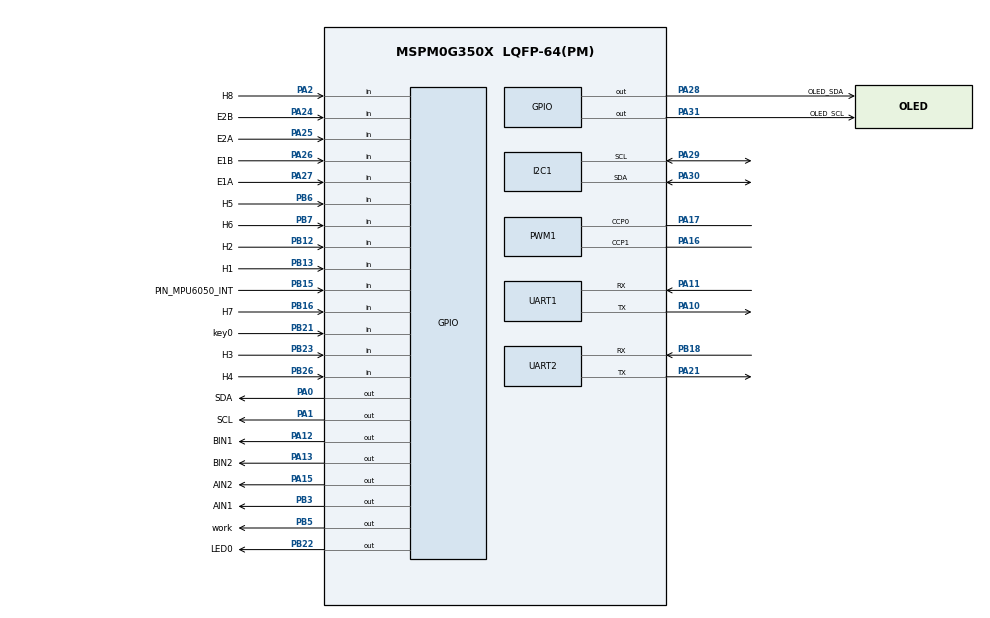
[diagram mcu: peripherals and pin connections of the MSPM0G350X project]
/**
 * @cliArgs --device "MSPM0G350X" --part "Default" --package "LQFP-64(PM)" --product "mspm0_sdk@2.10.00.04"
 * @versions {"tool":"1.27.0+4565"}
 */

/**
 * Import the modules used in this configuration.
 */
const GPIO   = scripting.addModule("/ti/driverlib/GPIO", {}, false);
const GPIO1  = GPIO.addInstance();
const GPIO2  = GPIO.addInstance();
const GPIO3  = GPIO.addInstance();
const GPIO4  = GPIO.addInstance();
const GPIO5  = GPIO.addInstance();
const GPIO6  = GPIO.addInstance();
const GPIO7  = GPIO.addInstance();
const GPIO8  = GPIO.addInstance();
const GPIO9  = GPIO.addInstance();
const I2C    = scripting.addModule("/ti/driverlib/I2C", {}, false);
const I2C1   = I2C.addInstance();
const PWM    = scripting.addModule("/ti/driverlib/PWM", {}, false);
const PWM1   = PWM.addInstance();
const SYSCTL = scripting.addModule("/ti/driverlib/SYSCTL");
const TIMER  = scripting.addModule("/ti/driverlib/TIMER", {}, false);
const TIMER1 = TIMER.addInstance();
const UART   = scripting.addModule("/ti/driverlib/UART", {}, false);
const UART1  = UART.addInstance();
const UART2  = UART.addInstance();

/**
 * Write custom configuration values to the imported modules.
 */
GPIO1.$name                               = "ENCODER";
GPIO1.port                                = "PORTA";
GPIO1.associatedPins.create(4);
GPIO1.associatedPins[0].$name             = "E1A";
GPIO1.associatedPins[0].direction         = "INPUT";
GPIO1.associatedPins[0].interruptEn       = true;
GPIO1.associatedPins[0].polarity          = "RISE";
GPIO1.associatedPins[0].internalResistor  = "PULL_DOWN";
GPIO1.associatedPins[0].interruptPriority = "0";
GPIO1.associatedPins[0].assignedPin       = "27";
GPIO1.associatedPins[0].pin.$assign       = "PA27";
GPIO1.associatedPins[1].$name             = "E1B";
GPIO1.associatedPins[1].direction         = "INPUT";
GPIO1.associatedPins[1].interruptEn       = true;
GPIO1.associatedPins[1].polarity          = "RISE";
GPIO1.associatedPins[1].internalResistor  = "PULL_DOWN";
GPIO1.associatedPins[1].interruptPriority = "0";
GPIO1.associatedPins[1].assignedPin       = "26";
GPIO1.associatedPins[1].pin.$assign       = "PA26";
GPIO1.associatedPins[2].$name             = "E2A";
GPIO1.associatedPins[2].direction         = "INPUT";
GPIO1.associatedPins[2].interruptEn       = true;
GPIO1.associatedPins[2].polarity          = "RISE";
GPIO1.associatedPins[2].internalResistor  = "PULL_DOWN";
GPIO1.associatedPins[2].interruptPriority = "0";
GPIO1.associatedPins[2].assignedPin       = "25";
GPIO1.associatedPins[2].pin.$assign       = "PA25";
GPIO1.associatedPins[3].$name             = "E2B";
GPIO1.associatedPins[3].direction         = "INPUT";
GPIO1.associatedPins[3].interruptEn       = true;
GPIO1.associatedPins[3].polarity          = "RISE";
GPIO1.associatedPins[3].internalResistor  = "PULL_DOWN";
GPIO1.associatedPins[3].interruptPriority = "0";
GPIO1.associatedPins[3].assignedPin       = "24";
GPIO1.associatedPins[3].pin.$assign       = "PA24";

const Board = scripting.addModule("/ti/driverlib/Board", {}, false);

GPIO2.$name                         = "OLED";
GPIO2.port                          = "PORTA";
GPIO2.associatedPins.create(2);
GPIO2.associatedPins[0].$name       = "OLED_SCL";
GPIO2.associatedPins[0].assignedPin = "31";
GPIO2.associatedPins[0].pin.$assign = "PA31";
GPIO2.associatedPins[1].$name       = "OLED_SDA";
GPIO2.associatedPins[1].assignedPin = "28";
GPIO2.associatedPins[1].pin.$assign = "PA28";

GPIO3.$name                          = "MOTOR";
GPIO3.associatedPins.create(4);
GPIO3.associatedPins[0].$name        = "AIN1";
GPIO3.associatedPins[0].assignedPort = "PORTB";
GPIO3.associatedPins[0].assignedPin  = "3";
GPIO3.associatedPins[0].pin.$assign  = "PB3";
GPIO3.associatedPins[1].$name        = "AIN2";
GPIO3.associatedPins[1].assignedPort = "PORTA";
GPIO3.associatedPins[1].assignedPin  = "15";
GPIO3.associatedPins[1].pin.$assign  = "PA15";
GPIO3.associatedPins[2].$name        = "BIN1";
GPIO3.associatedPins[2].assignedPort = "PORTA";
GPIO3.associatedPins[2].assignedPin  = "12";
GPIO3.associatedPins[2].pin.$assign  = "PA12";
GPIO3.associatedPins[3].$name        = "BIN2";
GPIO3.associatedPins[3].assignedPort = "PORTA";
GPIO3.associatedPins[3].assignedPin  = "13";
GPIO3.associatedPins[3].pin.$assign  = "PA13";

GPIO4.$name                          = "IIC_Software";
GPIO4.port                           = "PORTA";
GPIO4.associatedPins.create(2);
GPIO4.associatedPins[0].$name        = "SDA";
GPIO4.associatedPins[0].initialValue = "SET";
GPIO4.associatedPins[0].ioStructure  = "OD";
GPIO4.associatedPins[0].assignedPin  = "0";
GPIO4.associatedPins[0].pin.$assign  = "PA0";
GPIO4.associatedPins[1].$name        = "SCL";
GPIO4.associatedPins[1].initialValue = "SET";
GPIO4.associatedPins[1].ioStructure  = "OD";
GPIO4.associatedPins[1].assignedPin  = "1";
GPIO4.associatedPins[1].pin.$assign  = "PA1";

GPIO5.$name                               = "GPIO_MPU6050";
GPIO5.associatedPins[0].$name             = "PIN_MPU6050_INT";
GPIO5.associatedPins[0].direction         = "INPUT";
GPIO5.associatedPins[0].internalResistor  = "PULL_UP";
GPIO5.associatedPins[0].interruptEn       = true;
GPIO5.associatedPins[0].interruptPriority = "1";
GPIO5.associatedPins[0].polarity          = "FALL";
GPIO5.associatedPins[0].assignedPort      = "PORTB";
GPIO5.associatedPins[0].assignedPin       = "15";
GPIO5.associatedPins[0].pin.$assign       = "PB15";

GPIO6.$name                         = "citie";
GPIO6.port                          = "PORTB";
GPIO6.associatedPins[0].$name       = "work";
GPIO6.associatedPins[0].assignedPin = "5";
GPIO6.associatedPins[0].pin.$assign = "PB5";

GPIO7.$name                              = "KEY";
GPIO7.associatedPins[0].$name            = "key0";
GPIO7.associatedPins[0].direction        = "INPUT";
GPIO7.associatedPins[0].assignedPort     = "PORTB";
GPIO7.associatedPins[0].assignedPin      = "21";
GPIO7.associatedPins[0].internalResistor = "PULL_UP";
GPIO7.associatedPins[0].pin.$assign      = "PB21";

GPIO8.$name                          = "LED";
GPIO8.associatedPins[0].$name        = "LED0";
GPIO8.associatedPins[0].assignedPort = "PORTB";
GPIO8.associatedPins[0].assignedPin  = "22";
GPIO8.associatedPins[0].pin.$assign  = "PB22";

GPIO9.$name                          = "Huidu";
GPIO9.associatedPins.create(8);
GPIO9.associatedPins[0].$name        = "H1";
GPIO9.associatedPins[0].direction    = "INPUT";
GPIO9.associatedPins[0].assignedPin  = "13";
GPIO9.associatedPins[0].pin.$assign  = "PB13";
GPIO9.associatedPins[1].$name        = "H2";
GPIO9.associatedPins[1].direction    = "INPUT";
GPIO9.associatedPins[1].assignedPin  = "12";
GPIO9.associatedPins[1].pin.$assign  = "PB12";
GPIO9.associatedPins[2].$name        = "H3";
GPIO9.associatedPins[2].direction    = "INPUT";
GPIO9.associatedPins[2].assignedPin  = "23";
GPIO9.associatedPins[2].pin.$assign  = "PB23";
GPIO9.associatedPins[3].$name        = "H4";
GPIO9.associatedPins[3].direction    = "INPUT";
GPIO9.associatedPins[3].assignedPin  = "26";
GPIO9.associatedPins[3].pin.$assign  = "PB26";
GPIO9.associatedPins[4].$name        = "H5";
GPIO9.associatedPins[4].assignedPin  = "6";
GPIO9.associatedPins[4].direction    = "INPUT";
GPIO9.associatedPins[4].pin.$assign  = "PB6";
GPIO9.associatedPins[5].$name        = "H6";
GPIO9.associatedPins[5].assignedPin  = "7";
GPIO9.associatedPins[5].direction    = "INPUT";
GPIO9.associatedPins[5].pin.$assign  = "PB7";
GPIO9.associatedPins[6].$name        = "H7";
GPIO9.associatedPins[6].assignedPin  = "16";
GPIO9.associatedPins[6].assignedPort = "PORTB";
GPIO9.associatedPins[6].direction    = "INPUT";
GPIO9.associatedPins[6].pin.$assign  = "PB16";
GPIO9.associatedPins[7].$name        = "H8";
GPIO9.associatedPins[7].assignedPort = "PORTA";
GPIO9.associatedPins[7].assignedPin  = "2";
GPIO9.associatedPins[7].direction    = "INPUT";
GPIO9.associatedPins[7].pin.$assign  = "PA2";

I2C1.$name                             = "I2C_MPU6050";
I2C1.basicEnableController             = true;
I2C1.basicControllerStandardBusSpeed   = "Fast";
I2C1.peripheral.$assign                = "I2C1";
I2C1.peripheral.sdaPin.$assign         = "PA30";
I2C1.peripheral.sclPin.$assign         = "PA29";
I2C1.sdaPinConfig.hideOutputInversion  = scripting.forceWrite(false);
I2C1.sdaPinConfig.onlyInternalResistor = scripting.forceWrite(false);
I2C1.sdaPinConfig.passedPeripheralType = scripting.forceWrite("Digital");
I2C1.sdaPinConfig.$name                = "ti_driverlib_gpio_GPIOPinGeneric6";
I2C1.sclPinConfig.hideOutputInversion  = scripting.forceWrite(false);
I2C1.sclPinConfig.onlyInternalResistor = scripting.forceWrite(false);
I2C1.sclPinConfig.passedPeripheralType = scripting.forceWrite("Digital");
I2C1.sclPinConfig.$name                = "ti_driverlib_gpio_GPIOPinGeneric7";

PWM1.$name                              = "PWM_MOTOR";
PWM1.timerStartTimer                    = true;
PWM1.pwmMode                            = "EDGE_ALIGN_UP";
PWM1.peripheral.$assign                 = "TIMA1";
PWM1.peripheral.ccp0Pin.$assign         = "PA17";
PWM1.peripheral.ccp1Pin.$assign         = "PA16";
PWM1.PWM_CHANNEL_0.$name                = "ti_driverlib_pwm_PWMTimerCC0";
PWM1.PWM_CHANNEL_0.ccValue              = 500;
PWM1.PWM_CHANNEL_1.$name                = "ti_driverlib_pwm_PWMTimerCC1";
PWM1.PWM_CHANNEL_1.ccValue              = 500;
PWM1.ccp0PinConfig.direction            = scripting.forceWrite("OUTPUT");
PWM1.ccp0PinConfig.hideOutputInversion  = scripting.forceWrite(false);
PWM1.ccp0PinConfig.onlyInternalResistor = scripting.forceWrite(false);
PWM1.ccp0PinConfig.passedPeripheralType = scripting.forceWrite("Digital");
PWM1.ccp0PinConfig.$name                = "ti_driverlib_gpio_GPIOPinGeneric4";
PWM1.ccp1PinConfig.direction            = scripting.forceWrite("OUTPUT");
PWM1.ccp1PinConfig.hideOutputInversion  = scripting.forceWrite(false);
PWM1.ccp1PinConfig.onlyInternalResistor = scripting.forceWrite(false);
PWM1.ccp1PinConfig.passedPeripheralType = scripting.forceWrite("Digital");
PWM1.ccp1PinConfig.$name                = "ti_driverlib_gpio_GPIOPinGeneric5";

SYSCTL.forceDefaultClkConfig = true;

TIMER1.timerMode          = "PERIODIC";
TIMER1.interrupts         = ["ZERO"];
TIMER1.timerStartTimer    = true;
TIMER1.$name              = "TIMER_ENCODER";
TIMER1.timerClkDiv        = 8;
TIMER1.interruptPriority  = "0";
TIMER1.timerClkPrescale   = 10;
TIMER1.timerPeriod        = "10 ms";
TIMER1.peripheral.$assign = "TIMA0";

UART1.$name                    = "UART_0";
UART1.enabledInterrupts        = ["RX"];
UART1.interruptPriority        = "0";
UART1.peripheral.$assign       = "UART0";
UART1.peripheral.rxPin.$assign = "PA11";
UART1.peripheral.txPin.$assign = "PA10";
UART1.txPinConfig.$name        = "ti_driverlib_gpio_GPIOPinGeneric0";
UART1.rxPinConfig.$name        = "ti_driverlib_gpio_GPIOPinGeneric1";

UART2.$name                            = "Bluetooth";
UART2.enabledInterrupts                = ["RX"];
UART2.interruptPriority                = "0";
UART2.peripheral.$assign               = "UART2";
UART2.peripheral.rxPin.$assign         = "PB18";
UART2.peripheral.txPin.$assign         = "PA21";
UART2.txPinConfig.direction            = scripting.forceWrite("OUTPUT");
UART2.txPinConfig.hideOutputInversion  = scripting.forceWrite(false);
UART2.txPinConfig.onlyInternalResistor = scripting.forceWrite(false);
UART2.txPinConfig.passedPeripheralType = scripting.forceWrite("Digital");
UART2.txPinConfig.$name                = "ti_driverlib_gpio_GPIOPinGeneric2";
UART2.rxPinConfig.hideOutputInversion  = scripting.forceWrite(false);
UART2.rxPinConfig.onlyInternalResistor = scripting.forceWrite(false);
UART2.rxPinConfig.passedPeripheralType = scripting.forceWrite("Digital");
UART2.rxPinConfig.$name                = "ti_driverlib_gpio_GPIOPinGeneric3";

/**
 * Pinmux solution for unlocked pins/peripherals. This ensures that minor changes to the automatic solver in a future
 * version of the tool will not impact the pinmux you originally saw.  These lines can be completely deleted in order to
 * re-solve from scratch.
 */
Board.peripheral.$suggestSolution          = "DEBUGSS";
Board.peripheral.swclkPin.$suggestSolution = "PA20";
Board.peripheral.swdioPin.$suggestSolution = "PA19";
SYSCTL.peripheral.$suggestSolution         = "SYSCTL";
